VERSION ""

NS_ :

BS_:

BU_: ECU

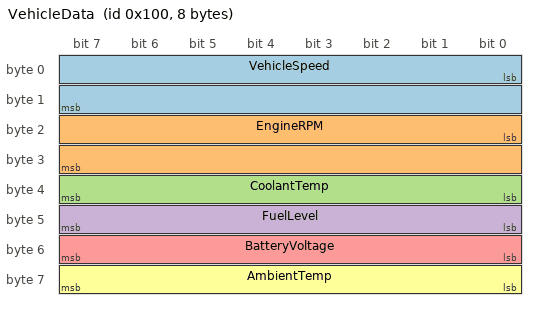
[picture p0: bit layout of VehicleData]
BO_ 256 VehicleData: 8 ECU
 SG_ VehicleSpeed : 0|16@1+ (1,0) [0|120] "km/h" ECU
 SG_ EngineRPM : 16|16@1+ (1,0) [800|5000] "rpm" ECU
 SG_ CoolantTemp : 32|8@1+ (1,0) [20|120] "degC" ECU
 SG_ FuelLevel : 40|8@1+ (1,0) [0|100] "%" ECU
 SG_ BatteryVoltage : 48|8@1+ (0.2,0) [11|15] "V" ECU
 SG_ AmbientTemp : 56|8@1+ (1,0) [0|50] "degC" ECU
